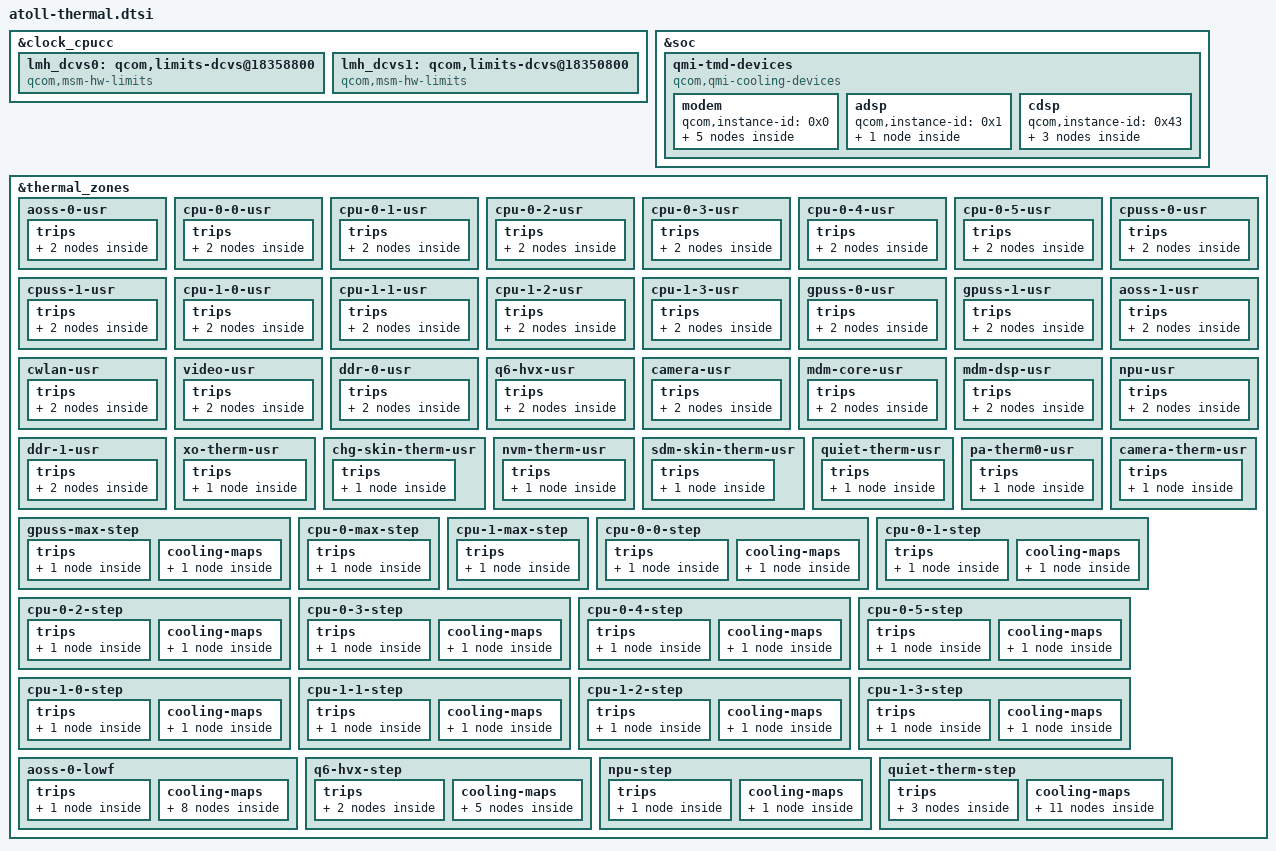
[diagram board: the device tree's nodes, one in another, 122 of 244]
/*
 * Copyright (c) 2019, The Linux Foundation. All rights reserved.
 *
 * This program is free software; you can redistribute it and/or modify
 * it under the terms of the GNU General Public License version 2 and
 * only version 2 as published by the Free Software Foundation.
 *
 * This program is distributed in the hope that it will be useful,
 * but WITHOUT ANY WARRANTY; without even the implied warranty of
 * MERCHANTABILITY or FITNESS FOR A PARTICULAR PURPOSE.  See the
 * GNU General Public License for more details.
 */

#include <dt-bindings/thermal/thermal.h>

&clock_cpucc {
	#address-cells = <1>;
	#size-cells = <1>;
	lmh_dcvs0: qcom,limits-dcvs@18358800 {
		compatible = "qcom,msm-hw-limits";
		interrupts = <GIC_SPI 32 IRQ_TYPE_LEVEL_HIGH>;
		qcom,affinity = <0>;
		reg = <0x18358800 0x1000>,
			<0x18323000 0x1000>;
		#thermal-sensor-cells = <0>;
	};

	lmh_dcvs1: qcom,limits-dcvs@18350800 {
		compatible = "qcom,msm-hw-limits";
		interrupts = <GIC_SPI 33 IRQ_TYPE_LEVEL_HIGH>;
		qcom,affinity = <1>;
		reg = <0x18350800 0x1000>,
			<0x18325800 0x1000>;
		#thermal-sensor-cells = <0>;
	};
};

&soc {
	qmi-tmd-devices {
		compatible = "qcom,qmi-cooling-devices";

		modem {
			qcom,instance-id = <0x0>;

			modem_pa: modem_pa {
				qcom,qmi-dev-name = "pa";
				#cooling-cells = <2>;
			};

			modem_proc: modem_proc {
				qcom,qmi-dev-name = "modem";
				#cooling-cells = <2>;
			};

			modem_current: modem_current {
				qcom,qmi-dev-name = "modem_current";
				#cooling-cells = <2>;
			};

			modem_skin: modem_skin {
				qcom,qmi-dev-name = "modem_skin";
				#cooling-cells = <2>;
			};

			modem_vdd: modem_vdd {
				qcom,qmi-dev-name = "cpuv_restriction_cold";
				#cooling-cells = <2>;
			};
		};

		adsp {
			qcom,instance-id = <0x1>;

			adsp_vdd: adsp_vdd {
				qcom,qmi-dev-name = "cpuv_restriction_cold";
				#cooling-cells = <2>;
			};
		};

		cdsp {
			qcom,instance-id = <0x43>;

			cdsp_vdd: cdsp_vdd {
				qcom,qmi-dev-name = "cpuv_restriction_cold";
				#cooling-cells = <2>;
			};

			cdsp_sw: cdsp {
				qcom,qmi-dev-name = "cdsp_sw";
				#cooling-cells = <2>;
			};

			cdsp_hw: hvx {
				qcom,qmi-dev-name = "cdsp_hw";
				#cooling-cells = <2>;
			};
		};
	};
};

&thermal_zones {
	aoss-0-usr {
		polling-delay-passive = <0>;
		polling-delay = <0>;
		thermal-governor = "user_space";
		thermal-sensors = <&tsens0 0>;
		wake-capable-sensor;
		trips {
			active-config0 {
				temperature = <125000>;
				hysteresis = <1000>;
				type = "passive";
			};
			reset-mon-cfg {
				temperature = <115000>;
				hysteresis = <5000>;
				type = "passive";
			};
		};
	};

	cpu-0-0-usr {
		polling-delay-passive = <0>;
		polling-delay = <0>;
		thermal-governor = "user_space";
		thermal-sensors = <&tsens0 1>;
		wake-capable-sensor;
		trips {
			active-config0 {
				temperature = <125000>;
				hysteresis = <1000>;
				type = "passive";
			};
			reset-mon-cfg {
				temperature = <115000>;
				hysteresis = <5000>;
				type = "passive";
			};
		};
	};

	cpu-0-1-usr {
		polling-delay-passive = <0>;
		polling-delay = <0>;
		thermal-governor = "user_space";
		thermal-sensors = <&tsens0 2>;
		wake-capable-sensor;
		trips {
			active-config0 {
				temperature = <125000>;
				hysteresis = <1000>;
				type = "passive";
			};
			reset-mon-cfg {
				temperature = <115000>;
				hysteresis = <5000>;
				type = "passive";
			};
		};
	};

	cpu-0-2-usr {
		polling-delay-passive = <0>;
		polling-delay = <0>;
		thermal-governor = "user_space";
		thermal-sensors = <&tsens0 3>;
		wake-capable-sensor;
		trips {
			active-config0 {
				temperature = <125000>;
				hysteresis = <1000>;
				type = "passive";
			};
			reset-mon-cfg {
				temperature = <115000>;
				hysteresis = <5000>;
				type = "passive";
			};
		};
	};

	cpu-0-3-usr {
		polling-delay-passive = <0>;
		polling-delay = <0>;
		thermal-sensors = <&tsens0 4>;
		thermal-governor = "user_space";
		wake-capable-sensor;
		trips {
			active-config0 {
				temperature = <125000>;
				hysteresis = <1000>;
				type = "passive";
			};
			reset-mon-cfg {
				temperature = <115000>;
				hysteresis = <5000>;
				type = "passive";
			};
		};
	};

	cpu-0-4-usr {
		polling-delay-passive = <0>;
		polling-delay = <0>;
		thermal-sensors = <&tsens0 5>;
		thermal-governor = "user_space";
		wake-capable-sensor;
		trips {
			active-config0 {
				temperature = <125000>;
				hysteresis = <1000>;
				type = "passive";
			};
			reset-mon-cfg {
				temperature = <115000>;
				hysteresis = <5000>;
				type = "passive";
			};
		};
	};

	cpu-0-5-usr {
		polling-delay-passive = <0>;
		polling-delay = <0>;
		thermal-sensors = <&tsens0 6>;
		thermal-governor = "user_space";
		wake-capable-sensor;
		trips {
			active-config0 {
				temperature = <125000>;
				hysteresis = <1000>;
				type = "passive";
			};
			reset-mon-cfg {
				temperature = <115000>;
				hysteresis = <5000>;
				type = "passive";
			};
		};
	};

	cpuss-0-usr {
		polling-delay-passive = <0>;
		polling-delay = <0>;
		thermal-sensors = <&tsens0 7>;
		thermal-governor = "user_space";
		wake-capable-sensor;
		trips {
			active-config0 {
				temperature = <125000>;
				hysteresis = <1000>;
				type = "passive";
			};
			reset-mon-cfg {
				temperature = <115000>;
				hysteresis = <5000>;
				type = "passive";
			};
		};
	};

	cpuss-1-usr {
		polling-delay-passive = <0>;
		polling-delay = <0>;
		thermal-sensors = <&tsens0 8>;
		thermal-governor = "user_space";
		wake-capable-sensor;
		trips {
			active-config0 {
				temperature = <125000>;
				hysteresis = <1000>;
				type = "passive";
			};
			reset-mon-cfg {
				temperature = <115000>;
				hysteresis = <5000>;
				type = "passive";
			};
		};
	};

	cpu-1-0-usr {
		polling-delay-passive = <0>;
		polling-delay = <0>;
		thermal-sensors = <&tsens0 9>;
		thermal-governor = "user_space";
		wake-capable-sensor;
		trips {
			active-config0 {
				temperature = <125000>;
				hysteresis = <1000>;
				type = "passive";
			};
			reset-mon-cfg {
				temperature = <115000>;
				hysteresis = <5000>;
				type = "passive";
			};
		};
	};

	cpu-1-1-usr {
		polling-delay-passive = <0>;
		polling-delay = <0>;
		thermal-sensors = <&tsens0 10>;
		thermal-governor = "user_space";
		wake-capable-sensor;
		trips {
			active-config0 {
				temperature = <125000>;
				hysteresis = <1000>;
				type = "passive";
			};
			reset-mon-cfg {
				temperature = <115000>;
				hysteresis = <5000>;
				type = "passive";
			};
		};
	};

	cpu-1-2-usr {
		polling-delay-passive = <0>;
		polling-delay = <0>;
		thermal-sensors = <&tsens0 11>;
		thermal-governor = "user_space";
		wake-capable-sensor;
		trips {
			active-config0 {
				temperature = <125000>;
				hysteresis = <1000>;
				type = "passive";
			};
			reset-mon-cfg {
				temperature = <115000>;
				hysteresis = <5000>;
				type = "passive";
			};
		};
	};

	cpu-1-3-usr {
		polling-delay-passive = <0>;
		polling-delay = <0>;
		thermal-sensors = <&tsens0 12>;
		thermal-governor = "user_space";
		wake-capable-sensor;
		trips {
			active-config0 {
				temperature = <125000>;
				hysteresis = <1000>;
				type = "passive";
			};
			reset-mon-cfg {
				temperature = <115000>;
				hysteresis = <5000>;
				type = "passive";
			};
		};
	};

	gpuss-0-usr {
		polling-delay-passive = <0>;
		polling-delay = <0>;
		thermal-sensors = <&tsens0 13>;
		thermal-governor = "user_space";
		wake-capable-sensor;
		trips {
			active-config0 {
				temperature = <125000>;
				hysteresis = <1000>;
				type = "passive";
			};
			reset-mon-cfg {
				temperature = <115000>;
				hysteresis = <5000>;
				type = "passive";
			};
		};
	};

	gpuss-1-usr {
		polling-delay-passive = <0>;
		polling-delay = <0>;
		thermal-sensors = <&tsens0 14>;
		thermal-governor = "user_space";
		wake-capable-sensor;
		trips {
			active-config0 {
				temperature = <125000>;
				hysteresis = <1000>;
				type = "passive";
			};
			reset-mon-cfg {
				temperature = <115000>;
				hysteresis = <5000>;
				type = "passive";
			};
		};
	};

	aoss-1-usr {
		polling-delay-passive = <0>;
		polling-delay = <0>;
		thermal-sensors = <&tsens1 0>;
		thermal-governor = "user_space";
		wake-capable-sensor;
		trips {
			active-config0 {
				temperature = <125000>;
				hysteresis = <1000>;
				type = "passive";
			};
			reset-mon-cfg {
				temperature = <115000>;
				hysteresis = <5000>;
				type = "passive";
			};
		};
	};

	cwlan-usr {
		polling-delay-passive = <0>;
		polling-delay = <0>;
		thermal-sensors = <&tsens1 1>;
		thermal-governor = "user_space";
		wake-capable-sensor;
		trips {
			active-config0 {
				temperature = <125000>;
				hysteresis = <1000>;
				type = "passive";
			};
			reset-mon-cfg {
				temperature = <115000>;
				hysteresis = <5000>;
				type = "passive";
			};
		};
	};

	video-usr {
		polling-delay-passive = <0>;
		polling-delay = <0>;
		thermal-sensors = <&tsens1 2>;
		thermal-governor = "user_space";
		wake-capable-sensor;
		trips {
			active-config0 {
				temperature = <125000>;
				hysteresis = <1000>;
				type = "passive";
			};
			reset-mon-cfg {
				temperature = <115000>;
				hysteresis = <5000>;
				type = "passive";
			};
		};
	};

	ddr-0-usr {
		polling-delay-passive = <0>;
		polling-delay = <0>;
		thermal-sensors = <&tsens1 3>;
		thermal-governor = "user_space";
		wake-capable-sensor;
		trips {
			active-config0 {
				temperature = <125000>;
				hysteresis = <1000>;
				type = "passive";
			};
			reset-mon-cfg {
				temperature = <115000>;
				hysteresis = <5000>;
				type = "passive";
			};
		};
	};

	q6-hvx-usr {
		polling-delay-passive = <0>;
		polling-delay = <0>;
		thermal-sensors = <&tsens1 4>;
		thermal-governor = "user_space";
		wake-capable-sensor;
		trips {
			active-config0 {
				temperature = <125000>;
				hysteresis = <1000>;
				type = "passive";
			};
			reset-mon-cfg {
				temperature = <115000>;
				hysteresis = <5000>;
				type = "passive";
			};
		};
	};

	camera-usr {
		polling-delay-passive = <0>;
		polling-delay = <0>;
		thermal-sensors = <&tsens1 5>;
		thermal-governor = "user_space";
		wake-capable-sensor;
		trips {
			active-config0 {
				temperature = <125000>;
				hysteresis = <1000>;
				type = "passive";
			};
			reset-mon-cfg {
				temperature = <115000>;
				hysteresis = <5000>;
				type = "passive";
			};
		};
	};

	mdm-core-usr {
		polling-delay-passive = <0>;
		polling-delay = <0>;
		thermal-sensors = <&tsens1 6>;
		thermal-governor = "user_space";
		wake-capable-sensor;
		trips {
			active-config0 {
				temperature = <125000>;
				hysteresis = <1000>;
				type = "passive";
			};
			reset-mon-cfg {
				temperature = <115000>;
				hysteresis = <5000>;
				type = "passive";
			};
		};
	};

	mdm-dsp-usr {
		polling-delay-passive = <0>;
		polling-delay = <0>;
		thermal-sensors = <&tsens1 7>;
		thermal-governor = "user_space";
		wake-capable-sensor;
		trips {
			active-config0 {
				temperature = <125000>;
				hysteresis = <1000>;
				type = "passive";
			};
			reset-mon-cfg {
				temperature = <115000>;
				hysteresis = <5000>;
				type = "passive";
			};
		};
	};

	npu-usr {
		polling-delay-passive = <0>;
		polling-delay = <0>;
		thermal-sensors = <&tsens1 8>;
		thermal-governor = "user_space";
		wake-capable-sensor;
		trips {
			active-config0 {
				temperature = <125000>;
				hysteresis = <1000>;
				type = "passive";
			};
			reset-mon-cfg {
				temperature = <115000>;
				hysteresis = <5000>;
				type = "passive";
			};
		};
	};

	ddr-1-usr {
		polling-delay-passive = <0>;
		polling-delay = <0>;
		thermal-sensors = <&tsens1 9>;
		thermal-governor = "user_space";
		wake-capable-sensor;
		trips {
			active-config0 {
				temperature = <125000>;
				hysteresis = <1000>;
				type = "passive";
			};
			reset-mon-cfg {
				temperature = <115000>;
				hysteresis = <5000>;
				type = "passive";
			};
		};
	};

	xo-therm-usr {
		polling-delay-passive = <0>;
		polling-delay = <0>;
		thermal-governor = "user_space";
		thermal-sensors = <&pm6150_adc_tm ADC_XO_THERM_PU2>;
		wake-capable-sensor;
		trips {
			active-config0 {
				temperature = <125000>;
				hysteresis = <1000>;
				type = "passive";
			};
		};
	};

	chg-skin-therm-usr {
		polling-delay-passive = <0>;
		polling-delay = <0>;
		thermal-governor = "user_space";
		thermal-sensors = <&pm6150_adc_tm ADC_AMUX_THM1_PU2>;
		wake-capable-sensor;
		trips {
			active-config0 {
				temperature = <125000>;
				hysteresis = <1000>;
				type = "passive";
			};
		};
	};

	nvm-therm-usr {
		polling-delay-passive = <0>;
		polling-delay = <0>;
		thermal-governor = "user_space";
		thermal-sensors = <&pm6150_adc_tm ADC_GPIO1_PU2>;
		wake-capable-sensor;
		trips {
			active-config0 {
				temperature = <125000>;
				hysteresis = <1000>;
				type = "passive";
			};
		};
	};

	sdm-skin-therm-usr {
		polling-delay-passive = <0>;
		polling-delay = <0>;
		thermal-governor = "user_space";
		thermal-sensors = <&pm6150_adc_tm ADC_GPIO2_PU2>;
		wake-capable-sensor;
		trips {
			active-config0 {
				temperature = <125000>;
				hysteresis = <1000>;
				type = "passive";
			};
		};
	};

	quiet-therm-usr {
		polling-delay-passive = <0>;
		polling-delay = <0>;
		thermal-governor = "user_space";
		thermal-sensors = <&pm6150l_adc_tm ADC_AMUX_THM1_PU2>;
		wake-capable-sensor;
		trips {
			active-config0 {
				temperature = <125000>;
				hysteresis = <1000>;
				type = "passive";
			};
		};
	};

	pa-therm0-usr {
		polling-delay-passive = <0>;
		polling-delay = <0>;
		thermal-governor = "user_space";
		thermal-sensors = <&pm6150l_adc_tm ADC_AMUX_THM2_PU2>;
		wake-capable-sensor;
		trips {
			active-config0 {
				temperature = <125000>;
				hysteresis = <1000>;
				type = "passive";
			};
		};
	};

	camera-therm-usr {
		polling-delay-passive = <0>;
		polling-delay = <0>;
		thermal-governor = "user_space";
		thermal-sensors = <&pm6150l_adc_tm ADC_GPIO1_PU2>;
		wake-capable-sensor;
		trips {
			active-config0 {
				temperature = <125000>;
				hysteresis = <1000>;
				type = "passive";
			};
		};
	};

	gpuss-max-step {
		polling-delay-passive = <10>;
		polling-delay = <100>;
		thermal-governor = "step_wise";
		wake-capable-sensor;
		trips {
			gpu_trip: gpu-trip {
				temperature = <95000>;
				hysteresis = <0>;
				type = "passive";
			};
		};

		cooling-maps {
			gpu_cdev {
				trip = <&gpu_trip>;
				cooling-device = <&msm_gpu THERMAL_NO_LIMIT
							THERMAL_NO_LIMIT>;
			};
		};
	};

	cpu-0-max-step {
		polling-delay-passive = <0>;
		polling-delay = <0>;
		thermal-governor = "step_wise";
		wake-capable-sensor;
		trips {
			silver-trip {
				temperature = <120000>;
				hysteresis = <0>;
				type = "passive";
			};
		};
	};

	cpu-1-max-step {
		polling-delay-passive = <0>;
		polling-delay = <0>;
		thermal-governor = "step_wise";
		wake-capable-sensor;
		trips {
			gold-trip {
				temperature = <120000>;
				hysteresis = <0>;
				type = "passive";
			};
		};
	};

	cpu-0-0-step {
		polling-delay-passive = <0>;
		polling-delay = <0>;
		thermal-governor = "step_wise";
		thermal-sensors = <&tsens0 1>;
		wake-capable-sensor;
		trips {
			cpu0_config: cpu0-config {
				temperature = <110000>;
				hysteresis = <10000>;
				type = "passive";
			};
		};
		cooling-maps {
			cpu0_cdev {
				trip = <&cpu0_config>;
				cooling-device =
					<&CPU0 THERMAL_MAX_LIMIT
						THERMAL_MAX_LIMIT>;
			};
		};
	};

	cpu-0-1-step {
		polling-delay-passive = <0>;
		polling-delay = <0>;
		thermal-governor = "step_wise";
		thermal-sensors = <&tsens0 2>;
		wake-capable-sensor;
		trips {
			cpu1_config: cpu1-config {
				temperature = <110000>;
				hysteresis = <10000>;
				type = "passive";
			};
		};
		cooling-maps {
			cpu1_cdev {
				trip = <&cpu1_config>;
				cooling-device =
					<&CPU1 THERMAL_MAX_LIMIT
						THERMAL_MAX_LIMIT>;
			};
		};
	};

	cpu-0-2-step {
		polling-delay-passive = <0>;
		polling-delay = <0>;
		thermal-governor = "step_wise";
		thermal-sensors = <&tsens0 3>;
		wake-capable-sensor;
		trips {
			cpu2_config: cpu2-config {
				temperature = <110000>;
				hysteresis = <10000>;
				type = "passive";
			};
		};
		cooling-maps {
			cpu2_cdev {
				trip = <&cpu2_config>;
				cooling-device =
					<&CPU2 THERMAL_MAX_LIMIT
						THERMAL_MAX_LIMIT>;
			};
		};
	};

	cpu-0-3-step {
		polling-delay-passive = <0>;
		polling-delay = <0>;
		thermal-governor = "step_wise";
		thermal-sensors = <&tsens0 4>;
		wake-capable-sensor;
		trips {
			cpu3_config: cpu3-config {
				temperature = <110000>;
				hysteresis = <10000>;
				type = "passive";
			};
		};
		cooling-maps {
			cpu3_cdev {
				trip = <&cpu3_config>;
				cooling-device =
					<&CPU3 THERMAL_MAX_LIMIT
						THERMAL_MAX_LIMIT>;
			};
		};
	};

	cpu-0-4-step {
		polling-delay-passive = <0>;
		polling-delay = <0>;
		thermal-governor = "step_wise";
		thermal-sensors = <&tsens0 5>;
		wake-capable-sensor;
		trips {
			cpu4_config: cpu4-config {
				temperature = <110000>;
				hysteresis = <10000>;
				type = "passive";
			};
		};
		cooling-maps {
			cpu4_cdev {
				trip = <&cpu4_config>;
				cooling-device =
					<&CPU4 THERMAL_MAX_LIMIT
						THERMAL_MAX_LIMIT>;
			};
		};
	};

	cpu-0-5-step {
		polling-delay-passive = <0>;
		polling-delay = <0>;
		thermal-governor = "step_wise";
		thermal-sensors = <&tsens0 6>;
		wake-capable-sensor;
		trips {
			cpu5_config: cpu5-config {
				temperature = <110000>;
				hysteresis = <10000>;
				type = "passive";
			};
		};
		cooling-maps {
			cpu5_cdev {
				trip = <&cpu5_config>;
				cooling-device =
					<&CPU5 THERMAL_MAX_LIMIT
						THERMAL_MAX_LIMIT>;
			};
		};
	};

	cpu-1-0-step {
		polling-delay-passive = <0>;
		polling-delay = <0>;
		thermal-governor = "step_wise";
		thermal-sensors = <&tsens0 9>;
		wake-capable-sensor;
		trips {
			cpu6_0_config: cpu6-0-config {
				temperature = <110000>;
				hysteresis = <10000>;
				type = "passive";
			};
		};
		cooling-maps {
			cpu6_cdev {
				trip = <&cpu6_0_config>;
				cooling-device =
					<&CPU6 THERMAL_MAX_LIMIT
						THERMAL_MAX_LIMIT>;
			};
		};
	};

	cpu-1-1-step {
		polling-delay-passive = <0>;
		polling-delay = <0>;
		thermal-governor = "step_wise";
		thermal-sensors = <&tsens0 10>;
		wake-capable-sensor;
		trips {
			cpu6_1_config: cpu6-1-config {
				temperature = <110000>;
				hysteresis = <10000>;
				type = "passive";
			};
		};
		cooling-maps {
			cpu6_cdev {
				trip = <&cpu6_1_config>;
				cooling-device =
					<&CPU6 THERMAL_MAX_LIMIT
						THERMAL_MAX_LIMIT>;
			};
		};
	};

	cpu-1-2-step {
		polling-delay-passive = <0>;
		polling-delay = <0>;
		thermal-governor = "step_wise";
		thermal-sensors = <&tsens0 11>;
		wake-capable-sensor;
		trips {
			cpu7_0_config: cpu7-0-config {
				temperature = <110000>;
				hysteresis = <10000>;
				type = "passive";
			};
		};
		cooling-maps {
			cpu7_cdev {
				trip = <&cpu7_0_config>;
				cooling-device =
					<&CPU7 THERMAL_MAX_LIMIT
						THERMAL_MAX_LIMIT>;
			};
		};
	};

	cpu-1-3-step {
		polling-delay-passive = <0>;
		polling-delay = <0>;
		thermal-governor = "step_wise";
		thermal-sensors = <&tsens0 12>;
		wake-capable-sensor;
		trips {
			cpu7_1_config: cpu7-1-config {
				temperature = <110000>;
				hysteresis = <10000>;
				type = "passive";
			};
		};
		cooling-maps {
			cpu7_cdev {
				trip = <&cpu7_1_config>;
				cooling-device =
					<&CPU7 THERMAL_MAX_LIMIT
						THERMAL_MAX_LIMIT>;
			};
		};
	};

	aoss-0-lowf {
		polling-delay-passive = <0>;
		polling-delay = <0>;
		thermal-governor = "low_limits_floor";
		thermal-sensors = <&tsens0 0>;
		wake-capable-sensor;
		tracks-low;
		trips {
			aoss0_trip: aoss0-trip {
				temperature = <5000>;
				hysteresis = <5000>;
				type = "passive";
			};
		};
		cooling-maps {
			cpu0_cdev {
				trip = <&aoss0_trip>;
				cooling-device = <&CPU0 2 2>;
			};
			cpu1_cdev {
				trip = <&aoss0_trip>;
				cooling-device = <&CPU6 4 4>;
			};
			gpu_vdd_cdev {
				trip = <&aoss0_trip>;
				cooling-device = <&msm_gpu (THERMAL_MAX_LIMIT-3)
							(THERMAL_MAX_LIMIT-3)>;
			};
			cx_vdd_cdev {
				trip = <&aoss0_trip>;
				cooling-device = <&cx_cdev 0 0>;
			};
			mx_vdd_cdev {
				trip = <&aoss0_trip>;
				cooling-device = <&mx_cdev 0 0>;
			};
			modem_vdd_cdev {
				trip = <&aoss0_trip>;
				cooling-device = <&modem_vdd 0 0>;
			};
			adsp_vdd_cdev {
				trip = <&aoss0_trip>;
				cooling-device = <&adsp_vdd 0 0>;
			};
			cdsp_vdd_cdev {
				trip = <&aoss0_trip>;
				cooling-device = <&cdsp_vdd 0 0>;
			};
		};
	};

	q6-hvx-step {
		polling-delay-passive = <10>;
		polling-delay = <0>;
		thermal-sensors = <&tsens1 4>;
		thermal-governor = "step_wise";
		wake-capable-sensor;
		trips {
			q6_hvx_trip0: q6-hvx-trip0 {
				temperature = <95000>;
				hysteresis = <0>;
				type = "passive";
			};

			q6_hvx_trip1: q6-hvx-trip1 {
				temperature = <100000>;
				hysteresis = <5000>;
				type = "passive";
			};
		};

		cooling-maps {
			cdsp-cdev0 {
				trip = <&q6_hvx_trip0>;
				cooling-device = <&cdsp_sw THERMAL_NO_LIMIT
							THERMAL_NO_LIMIT>;
			};

			cdsp-cx-cdev0 {
				trip = <&q6_hvx_trip1>;
				cooling-device = <&cdsp_sw THERMAL_MAX_LIMIT
							THERMAL_MAX_LIMIT>;
			};

			cdsp-cx-cdev1 {
				trip = <&q6_hvx_trip1>;
				cooling-device = <&msm_gpu (THERMAL_MAX_LIMIT-1)
							(THERMAL_MAX_LIMIT-1)>;
			};

			cdsp-cx-cdev2 {
				trip = <&q6_hvx_trip1>;
				cooling-device = <&modem_proc 3 3>;
			};

			cdsp-cx-cdev3 {
				trip = <&q6_hvx_trip1>;
				cooling-device = <&modem_pa 3 3>;
			};
		};
	};

	npu-step {
		polling-delay-passive = <10>;
		polling-delay = <0>;
		thermal-sensors = <&tsens1 8>;
		thermal-governor = "step_wise";
		wake-capable-sensor;
		trips {
			npu_trip0: npu-trip0 {
				temperature = <95000>;
				hysteresis = <0>;
				type = "passive";
			};
		};
		cooling-maps {
			npu_cdev {
				trip = <&npu_trip0>;
				cooling-device =
					<&msm_npu THERMAL_NO_LIMIT
						THERMAL_NO_LIMIT>;
			};
		};
	};

	quiet-therm-step {
		polling-delay-passive = <2000>;
		polling-delay = <0>;
		thermal-governor = "step_wise";
		thermal-sensors = <&pm6150l_adc_tm ADC_AMUX_THM1_PU2>;
		wake-capable-sensor;
		trips {
			skin_gold_trip: gold-trip {
				temperature = <48000>;
				hysteresis = <0>;
				type = "passive";
			};

			skin_cx_trip: skin-cx-trip {
				temperature = <50000>;
				hysteresis = <5000>;
				type = "passive";
			};

			skin_silver_trip: silver-trip {
				temperature = <52000>;
				hysteresis = <0>;
				type = "passive";
			};
		};

		cooling-maps {
			skin_cpu6 {
				trip = <&skin_gold_trip>;
				cooling-device =
					/* throttle from fmax to 1708800KHz */
					<&CPU6 THERMAL_NO_LIMIT
						(THERMAL_MAX_LIMIT-7)>;
			};
			skin_cpu7 {
				trip = <&skin_gold_trip>;
				cooling-device =
					<&CPU7 THERMAL_NO_LIMIT
						(THERMAL_MAX_LIMIT-7)>;
			};
			skin_cpu0 {
				trip = <&skin_silver_trip>;
				/* throttle from fmax to 1516800KHz */
				cooling-device = <&CPU0 THERMAL_NO_LIMIT
						(THERMAL_MAX_LIMIT-7)>;
			};
			skin_cpu1 {
				trip = <&skin_silver_trip>;
				cooling-device = <&CPU1 THERMAL_NO_LIMIT
						(THERMAL_MAX_LIMIT-7)>;
			};
			skin_cpu2 {
				trip = <&skin_silver_trip>;
				cooling-device = <&CPU2 THERMAL_NO_LIMIT
						(THERMAL_MAX_LIMIT-7)>;
			};
			skin_cpu3 {
				trip = <&skin_silver_trip>;
				cooling-device = <&CPU3 THERMAL_NO_LIMIT
						(THERMAL_MAX_LIMIT-7)>;
			};
			skin_cpu4 {
				trip = <&skin_silver_trip>;
				cooling-device = <&CPU4 THERMAL_NO_LIMIT
						(THERMAL_MAX_LIMIT-7)>;
			};
			skin_cpu5 {
				trip = <&skin_silver_trip>;
				cooling-device = <&CPU5 THERMAL_NO_LIMIT
						(THERMAL_MAX_LIMIT-7)>;
			};
			skin_gpu {
				trip = <&skin_cx_trip>;
				cooling-device = <&msm_gpu (THERMAL_MAX_LIMIT-1)
						(THERMAL_MAX_LIMIT-1)>;
			};
			skin_modem {
				trip = <&skin_cx_trip>;
				cooling-device = <&modem_pa 3 3>;
			};
			cdsp_cdev1 {
				trip = <&skin_cx_trip>;
				cooling-device = <&cdsp_sw THERMAL_MAX_LIMIT
							THERMAL_MAX_LIMIT>;
			};
		};
	};
};
